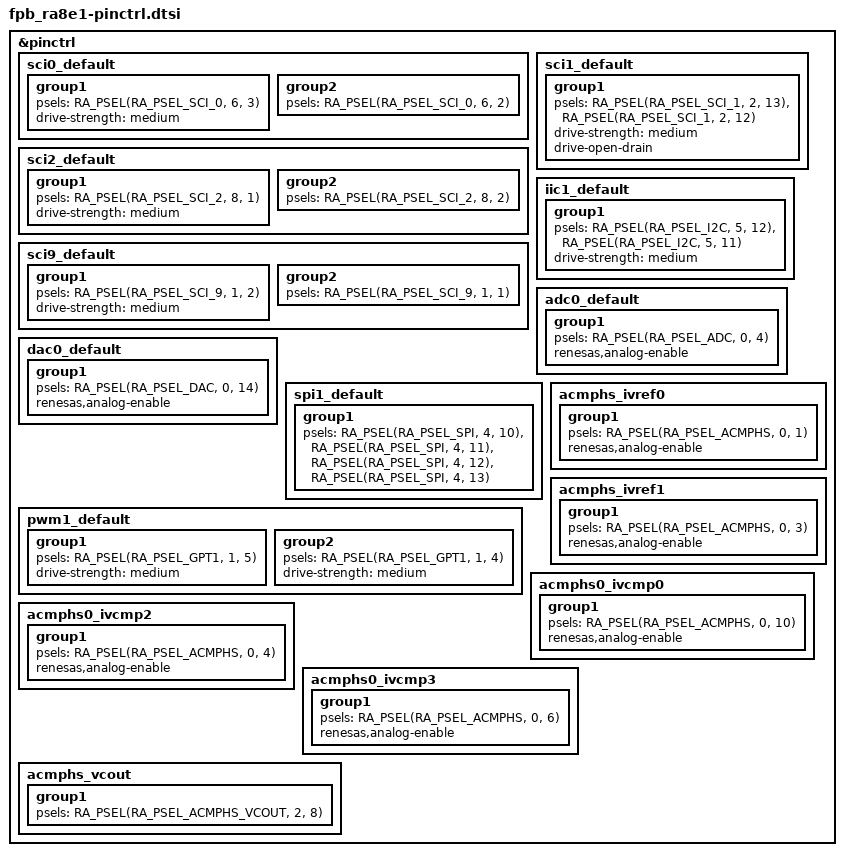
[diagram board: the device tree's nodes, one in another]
/*
 * Copyright (c) 2026 Renesas Electronics Corporation
 * SPDX-License-Identifier: Apache-2.0
 */

&pinctrl {
	sci0_default: sci0_default {
		group1 {
			/* tx */
			psels = <RA_PSEL(RA_PSEL_SCI_0, 6, 3)>;
			drive-strength = "medium";
		};

		group2 {
			/* rx */
			psels = <RA_PSEL(RA_PSEL_SCI_0, 6, 2)>;
		};
	};

	sci1_default: sci1_default {
		group1 {
			/* SDA SCL */
			psels = <RA_PSEL(RA_PSEL_SCI_1, 2, 13)>,
				<RA_PSEL(RA_PSEL_SCI_1, 2, 12)>;
			drive-strength = "medium";
			drive-open-drain;
		};
	};

	sci2_default: sci2_default {
		group1 {
			/* tx */
			psels = <RA_PSEL(RA_PSEL_SCI_2, 8, 1)>;
			drive-strength = "medium";
		};

		group2 {
			/* rx */
			psels = <RA_PSEL(RA_PSEL_SCI_2, 8, 2)>;
		};
	};

	sci9_default: sci9_default {
		group1 {
			/* tx */
			psels = <RA_PSEL(RA_PSEL_SCI_9, 1, 2)>;
			drive-strength = "medium";
		};

		group2 {
			/* rx */
			psels = <RA_PSEL(RA_PSEL_SCI_9, 1, 1)>;
		};
	};

	iic1_default: iic1_default {
		group1 {
			/* SCL1 SDA1*/
			psels = <RA_PSEL(RA_PSEL_I2C, 5, 12)>,
				<RA_PSEL(RA_PSEL_I2C, 5, 11)>;
			drive-strength = "medium";
		};
	};

	adc0_default: adc0_default {
		group1 {
			/* input */
			psels = <RA_PSEL(RA_PSEL_ADC, 0, 4)>;
			renesas,analog-enable;
		};
	};

	dac0_default: dac0_default {
		group1 {
			/* output */
			psels = <RA_PSEL(RA_PSEL_DAC, 0, 14)>;
			renesas,analog-enable;
		};
	};

	spi1_default: spi1_default {
		group1 {
			/* MISO MOSI RSPCK SSL*/
			psels = <RA_PSEL(RA_PSEL_SPI, 4, 10)>,
				<RA_PSEL(RA_PSEL_SPI, 4, 11)>,
				<RA_PSEL(RA_PSEL_SPI, 4, 12)>,
				<RA_PSEL(RA_PSEL_SPI, 4, 13)>;
		};
	};

	pwm1_default: pwm1_default {
		group1 {
			/* GTIOC1A */
			psels = <RA_PSEL(RA_PSEL_GPT1, 1, 5)>;
			drive-strength = "medium";
		};

		group2 {
			/* GTIOC1B */
			psels = <RA_PSEL(RA_PSEL_GPT1, 1, 4)>;
			drive-strength = "medium";
		};
	};

	/omit-if-no-ref/ acmphs_ivref0: acmphs_ivref0 {
		group1 {
			/* IVREF0 */
			psels = <RA_PSEL(RA_PSEL_ACMPHS, 0, 1)>;
			renesas,analog-enable;
		};
	};

	/omit-if-no-ref/ acmphs_ivref1: acmphs_ivref1 {
		group1 {
			/* IVREF1 */
			psels = <RA_PSEL(RA_PSEL_ACMPHS, 0, 3)>;
			renesas,analog-enable;
		};
	};

	/omit-if-no-ref/ acmphs0_ivcmp0: acmphs0_ivcmp0 {
		group1 {
			/* CH0 IVCMP0 */
			psels = <RA_PSEL(RA_PSEL_ACMPHS, 0, 10)>;
			renesas,analog-enable;
		};
	};

	/omit-if-no-ref/ acmphs0_ivcmp2: acmphs0_ivcmp2 {
		group1 {
			/* CH0 IVCMP2 */
			psels = <RA_PSEL(RA_PSEL_ACMPHS, 0, 4)>;
			renesas,analog-enable;
		};
	};

	/omit-if-no-ref/ acmphs0_ivcmp3: acmphs0_ivcmp3 {
		group1 {
			/* CH0 IVCMP3 */
			psels = <RA_PSEL(RA_PSEL_ACMPHS, 0, 6)>;
			renesas,analog-enable;
		};
	};

	/omit-if-no-ref/ acmphs_vcout: acmphs_vcout {
		group1 {
			/* VCOUT */
			psels = <RA_PSEL(RA_PSEL_ACMPHS_VCOUT, 2, 8)>;
		};
	};
};
